# dm648_cslr_vport_001 register map
Vendor: Texas Instruments
Peripheral module from a debugger description file.
Registers are 32-bit, access not given, reset 0x0 unless marked. A register's access mark holds for its fields unless they carry their own. Offsets are as the file gives them; lines under a group give offsets from that group; [hi:lo] are bit positions; {n}, {i} and the like mark numbered series; 'fields as' and 'values as' point back to an identical list; <NAME> marks a mode.

## VPORT — This module provides an interface to program the VPORT (Video Port) registers. These registers are memory mapped.
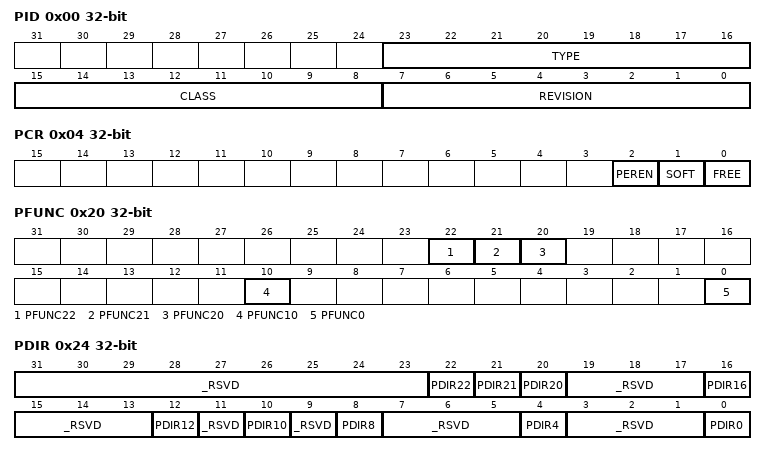
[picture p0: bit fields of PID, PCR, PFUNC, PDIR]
0x00 PID — Video Port Peripheral Identification Register
  [23:16] TYPE ro — Peripheral Type
  [15:8] CLASS ro — Peripheral Class
  [7:0] REVISION ro — Peripheral Revision
0x04 PCR — Video Port Peripheral Control Register
  [2] PEREN rw — Peripheral Enable
    0=INP_DIS; 1=PORT_FUNC
  [1] SOFT ro — Emulation suspend
    0=FLD_COMP_EMU_SUS; 1=ND
  [0] FREE rw — Port Operation during emulation suspension
    0=SOFT_DET; 1=PORT_ENA_EMU_SUS
0x20 PFUNC — Video Port Pin Function Register
  [22] PFUNC22 rw — Controls VCTL3
  [21] PFUNC21 rw — Controls VCTL2
  [20] PFUNC20 rw — Controls VCTL1
  [10] PFUNC10 rw — Controls VDATA[19:10]
    0=1BYTE
  [0] PFUNC0 rw — Controls VDATA[9:0]
0x24 PDIR — Video Port Direction Register
  [31:23] _RSVD — These bits are not used (access N)
  [22] PDIR22 rw — Controls VCTL3
  [21] PDIR21 rw — Controls VCTL2
  [20] PDIR20 rw — Controls VCTL1
  [19:17] _RSVD — These bits are not used (access N)
  [16] PDIR16 rw — Controls VDATA[19:16]
  [15:13] _RSVD — These bits are not used (access N)
  [12] PDIR12 rw — Controls VDATA[15:12]
  [11] _RSVD — These bits are not used (access N)
  [10] PDIR10 rw — Controls VDATA[11:10]
  [9] _RSVD — These bits are not used (access N)
  [8] PDIR8 rw — Controls VDATA[9:8]
  [7:5] _RSVD — These bits are not used (access N)
    1=ENABLE (Access the divisor latches)
  [4] PDIR4 rw — Controls VDATA[7:4]
    0=DISABLE (Access the RBR/THR and IER)
  [3:1] _RSVD — These bits are not used (access N)
  [0] PDIR0 rw — Controls VDATA[3:0]
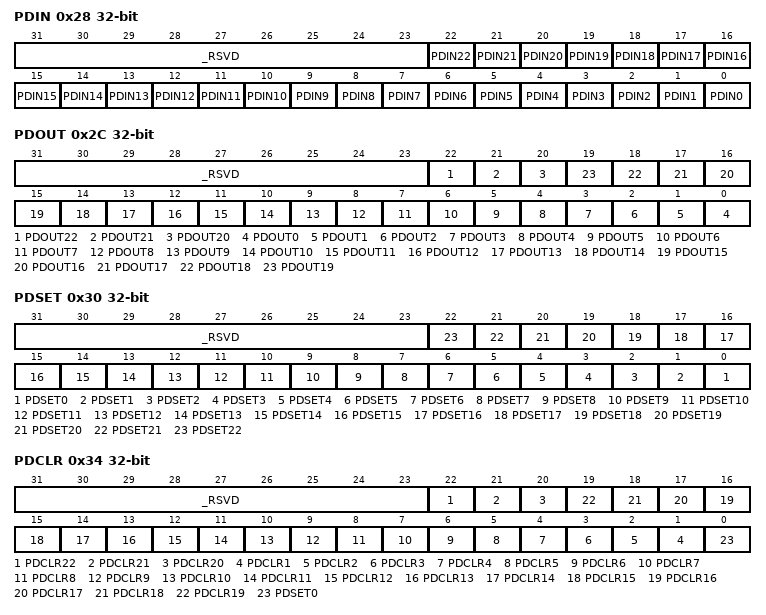
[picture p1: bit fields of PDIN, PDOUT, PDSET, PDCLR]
0x28 PDIN — Video Port Data In Register
  [31:23] _RSVD — These bits are not used (access N)
  [22] PDIN22 ro — Pin 22 returns the value of VCTL3 PIN
  [21] PDIN21 ro — Pin 21 returns the value of VCTL2 PIN
  [20] PDIN20 ro — Pin 20 returns the value of VCTL1 PIN
  [n] PDIN{n} ro (n=0..19) — Return the value of VDATA pins
0x2C PDOUT — Video Port Data Out Register
  [31:23] _RSVD — These bits are not used (access N)
  [22] PDOUT22 rw — Controls VCTL3
  [21] PDOUT21 rw — Controls VCTL2
  [20] PDOUT20 rw — Controls VCTL1
  [n] PDOUT{n} rw (n=0..19) — Controls VDATA
0x30 PDSET — Video Port Data Set Register
  [31:23] _RSVD — These bits are not used. (access N)
  [n] PDSET{n} rw (n=0..22) — Sets corresponding bit in PDOUT
0x34 PDCLR — Video Port Data Clear Register
  [31:23] _RSVD — These bits are not used. (access N)
  [22] PDCLR22 rw — Controls VCTL3
  [21] PDCLR21 rw — Controls VCTL2
  [20] PDCLR20 rw — Controls VCTL1
  [n] PDCLR{n} rw (n=1..19) — Clears corresponding bit in PDOUT
  [0] PDSET0 rw — Clears corresponding bit in PDOUT
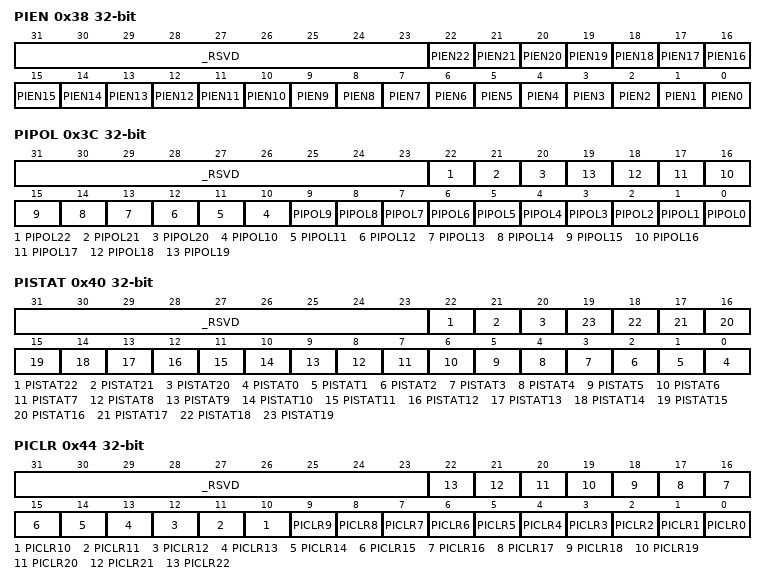
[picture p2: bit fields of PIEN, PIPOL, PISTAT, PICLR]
0x38 PIEN — Video Port Interrupt Enable
  [31:23] _RSVD — These bits are not used. (access N)
  [22] PIEN22 rw — Enable interrupt on VCTL3 pin
  [21] PIEN21 rw — Enable interrupt on VCTL2 pin
  [20] PIEN20 rw — Enable interrupt on VCTL1 pin
  [n] PIEN{n} rw (n=0..19) — Enable interrupt on corresponding VDATA pin
0x3C PIPOL — Video Port Interrupt Polarity Register
  [31:23] _RSVD — These bits are not used. (access N)
  [22] PIPOL22 rw — Controls interrupt on VCTL3
  [21] PIPOL21 rw — Controls interrupt on VCTL2
  [20] PIPOL20 rw — Controls interrupt on VCTL1
  [n] PIPOL{n} rw (n=2..19) — Controls interrupt on VDATA pin
  [1] PIPOL1 rw — Controls interrupt on VDATA
  [0] PIPOL0 rw — Controls interrupt on VDATA
0x40 PISTAT — Video Port Interrupt Status Register
  [31:23] _RSVD — These bits are not used. (access N)
  [22] PISTAT22 rw — Indicates pending interrupt on VCTL3 pin
  [21] PISTAT21 rw — Indicates pending interrupt on VCTL2 pin
  [20] PISTAT20 rw — Indicates pending interrupt on VCTL1 pin
  [n] PISTAT{n} rw (n=0..19) — Controls interrupt on VDATA pin
0x44 PICLR — Video Port Interrupt Clear Register
  [31:23] _RSVD — These bits are not used. (access N)
  [n] PICLR{n} rw (n=0..22) — Writing 1 to PICLR clears corresponding bit in PISTAT
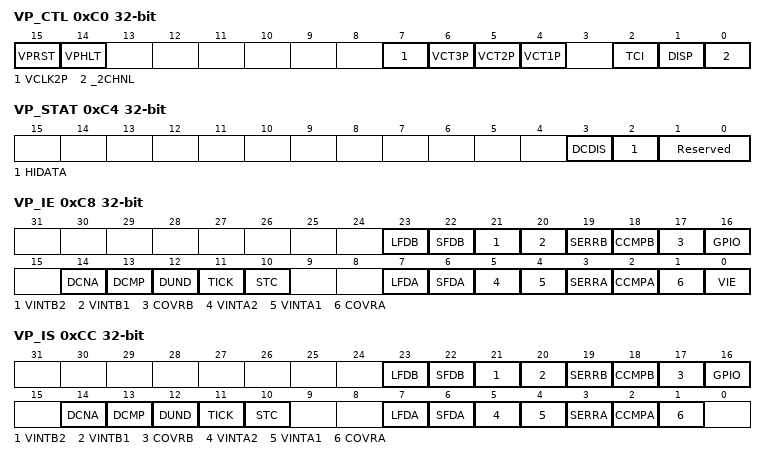
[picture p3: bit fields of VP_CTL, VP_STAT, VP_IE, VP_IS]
0xC0 VP_CTL — Video Port Control Register
  [15] VPRST ro — Video Port Software Reset
  [14] VPHLT ro — Video Port Halt
  [7] VCLK2P rw — VCTL1 Pin Polarity
  [6] VCT3P rw — VCTL1 Pin Polarity
  [5] VCT2P rw — VCTL1 Pin Polarity
  [4] VCT1P rw — VCTL1 Pin Polarity
  [2] TCI rw — TCI Capture Mode
  [1] DISP rw — Display Mode
  [0] _2CHNL rw — Dual Channel Mode
0xC4 VP_STAT — Video Port Status Register
  [3] DCDIS ro — Dual Channel Disabled
  [2] HIDATA ro — High Data Half bus
  [1:0] Reserved — (access N)
0xC8 VP_IE — Video Port Interrupt Enable Register
  [23] LFDB rw — Lonfg field detected
  [22] SFDB rw — Short field detected
  [21] VINTB2 rw — Field 2 vertical interrupt enable
  [20] VINTB1 rw — Field 1 Vertical interrupt enable
  [19] SERRB rw — Synchronization
  [18] CCMPB rw — Capture complete on A/B channel interrupt enable
  [17] COVRB rw — Capture overrun on A/B channel interrupt enable
  [16] GPIO rw — General Purpose I/O
  [14] DCNA rw — Display complete not acknowledge
  [13] DCMP rw — Display complete
  [12] DUND rw — Display underrun
  [11] TICK rw — Clock tick
  [10] STC rw — System time clock
  [7] LFDA rw — Lonfg field detected
  [6] SFDA rw — Short field detected
  [5] VINTA2 rw — Field 2 vertical interrupt enable
  [4] VINTA1 rw — Field 1 Vertical interrupt enable
  [3] SERRA rw — Synchronization
  [2] CCMPA rw — Capture complete on A/B channel interrupt enable
  [1] COVRA rw — Capture overrun on A/B channel interrupt enable
  [0] VIE rw — Video Port global interrupt enable
0xCC VP_IS — Video Port Interrupt Status Register
  [23] LFDB rw — Lonfg field detected
  [22] SFDB rw — Short field detected
  [21] VINTB2 rw — Field 2 vertical interrupt enable
  [20] VINTB1 rw — Field 1 Vertical interrupt enable
  [19] SERRB rw — Synchronization
  [18] CCMPB rw — Capture complete on A/B channel interrupt enable
  [17] COVRB rw — Capture overrun on A/B channel interrupt enable
  [16] GPIO rw — General Purpose I/O
  [14] DCNA rw — Display complete not acknowledge
  [13] DCMP rw — Display complete
  [12] DUND rw — Display underrun
  [11] TICK rw — Clock tick
  [10] STC rw — System time clock
  [7] LFDA rw — Lonfg field detected
  [6] SFDA rw — Short field detected
  [5] VINTA2 rw — Field 2 vertical interrupt enable
  [4] VINTA1 rw — Field 1 Vertical interrupt enable
  [3] SERRA rw — Synchronization
  [2] CCMPA rw — Capture complete on A/B channel interrupt enable
  [1] COVRA rw — Capture overrun on A/B channel interrupt enable
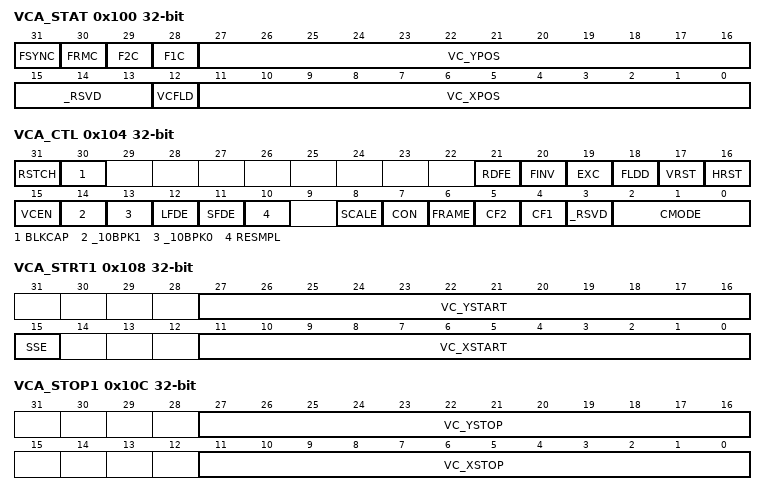
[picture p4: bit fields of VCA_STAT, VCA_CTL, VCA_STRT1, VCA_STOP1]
0x100 VCA_STAT — Video Capture Status Register
  [31] FSYNC ro — Sync to the current frame
  [30] FRMC ro — Indicates frame capture
  [29] F2C ro — Indicates field 2 capture
  [28] F1C ro — Indicates field 1 capture
  [27:16] VC_YPOS rw — Indicates line that is currently being received
  [15:13] _RSVD — These bits are not used. (access N)
  [12] VCFLD ro — Indicates which field is currently being captured
  [11:0] VC_XPOS ro — Pixel index of last received pixel
0x104 VCA_CTL — Video Capture Control Register
  [31] RSTCH rw
  [30] BLKCAP rw — Block
  [21] RDFE rw
  [20] FINV rw — Detected Field invert
  [19] EXC rw — Enable extenal control
  [18] FLDD rw — Field Detect
  [17] VRST rw — VCOUNT Reset method
  [16] HRST rw — HCOUNT reset method
  [15] VCEN rw — Video Capture Enable
  [14] _10BPK1 rw — Packing Format
  [13] _10BPK0 rw — Packing Format
  [12] LFDE rw — Long Field Detect
  [11] SFDE rw — Short Field Detect
  [10] RESMPL rw — Resampling
  [8] SCALE rw — Scaling
  [7] CON rw — Continuous capture enable
  [6] FRAME rw — Capture Frame
  [5] CF2 rw — Capture Field2
  [4] CF1 rw — Capture Field1
  [3] _RSVD — These bits are not used. (access N)
  [2:0] CMODE rw — Mode in which port should work
0x108 VCA_STRT1 — Video Captur Field1 Start Register
  [27:16] VC_YSTART — Starting Line Number
  [15] SSE rw — This bit determines over-sampling mode.
  [11:0] VC_XSTART — These bits are not used. (access N)
0x10C VCA_STOP1 — Video Capture Field1 Stop Register
  [27:16] VC_YSTOP rw — This bit determines over-sampling mode.
  [11:0] VC_XSTOP — These bits are not used. (access N)
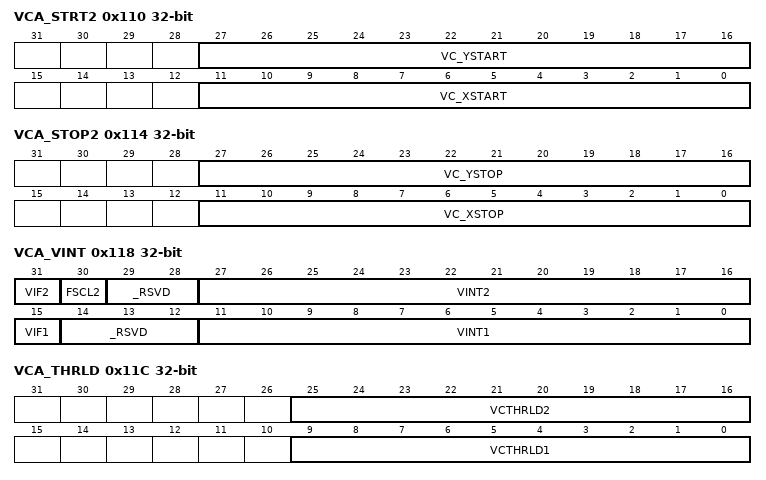
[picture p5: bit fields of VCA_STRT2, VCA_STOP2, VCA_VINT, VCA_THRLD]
0x110 VCA_STRT2 — Video Capture A Field2 Start Register
  [27:16] VC_YSTART rw — This bit determines over-sampling mode.
  [11:0] VC_XSTART — These bits are not used. (access N)
0x114 VCA_STOP2 — Video Capture A Field2 Stop Register
  fields as VCA_STOP1
0x118 VCA_VINT — Video Capture Vertical Interrupt Register
  [31] VIF2 rw — Enable setting of VINT in field 2
  [30] FSCL2 rw — FSYNC bit to be cleared in field 2
  [29:28] _RSVD — This bit determines over-sampling mode. (access N)
  [27:16] VINT2 rw — Line on which vertical interrupt occurs
  [15] VIF1 rw — Enable setting of VINT1 in field 1
  [14:12] _RSVD — These bits are not used. (access N)
  [11:0] VINT1 rw — Enable setting of VINT in field 2
0x11C VCA_THRLD — Video Capture Threshold Register
  [25:16] VCTHRLD2 rw — Field 2 threshold
  [9:0] VCTHRLD1 — Field 1 threshold (access N)
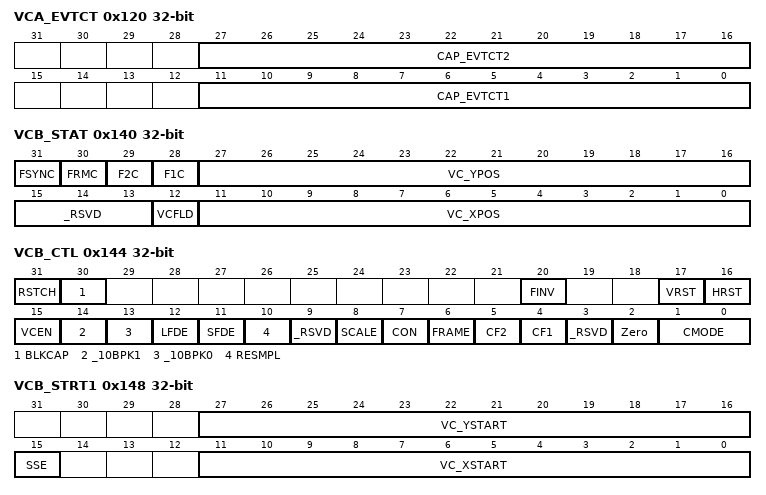
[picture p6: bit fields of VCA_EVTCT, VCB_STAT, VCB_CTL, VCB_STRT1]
0x120 VCA_EVTCT — Video Capture Event Count Register
  [27:16] CAP_EVTCT2 rw — DMA event for field 2 capture
  [11:0] CAP_EVTCT1 — DMA event for field 1 capture (access N)
0x140 VCB_STAT — Video Capture Status Register
  fields as VCA_STAT
0x144 VCB_CTL — Video Capture Control Register
  [31] RSTCH rw
  [30] BLKCAP rw — Block
  [20] FINV rw — Detected Field invert
  [17] VRST rw — VCOUNT Reset method
  [16] HRST rw — HCOUNT reset method
  [15] VCEN rw — Video Capture Enable
  [14] _10BPK1 rw — Packing Format
  [13] _10BPK0 rw — Packing Format
  [12] LFDE rw — Long Field Detect
  [11] SFDE rw — Short Field Detect
  [10] RESMPL rw — Resampling
  [9] _RSVD — Resampling (access N)
  [8] SCALE rw — Scaling
  [7] CON rw — Continuous capture enable
  [6] FRAME rw — Capture Frame
  [5] CF2 rw — Capture Field2
  [4] CF1 rw — Capture Field1
  [3] _RSVD — These bits are not used. (access N)
  [2] Zero ro — Value is zero
  [1:0] CMODE rw — Mode in which port should work
0x148 VCB_STRT1 — Video Captur Field1 Start Register
  fields as VCA_STRT1
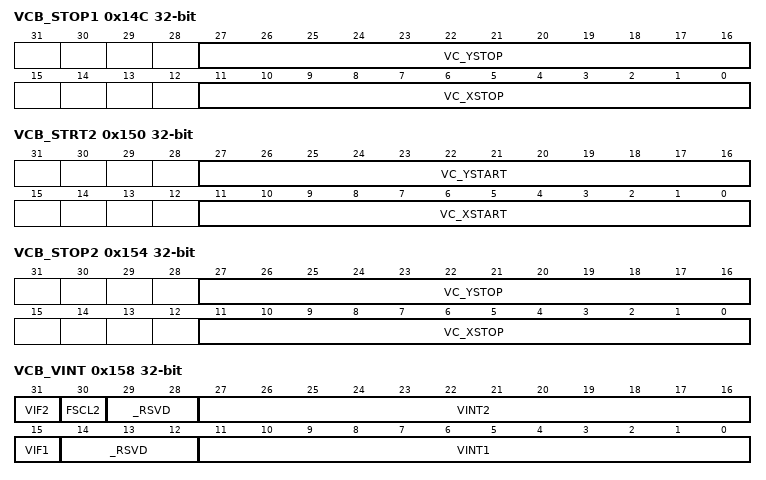
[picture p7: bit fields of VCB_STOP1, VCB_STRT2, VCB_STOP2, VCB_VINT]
0x14C VCB_STOP1 — Video Capture Field1 Stop Register
  fields as VCA_STOP1
0x150 VCB_STRT2 — Video Capture B Field2 Start Register
  fields as VCA_STRT2
0x154 VCB_STOP2 — Video Capture B Field2 Stop Register
  fields as VCA_STOP1
0x158 VCB_VINT — Video Capture Vertical Interrupt Register
  fields as VCA_VINT
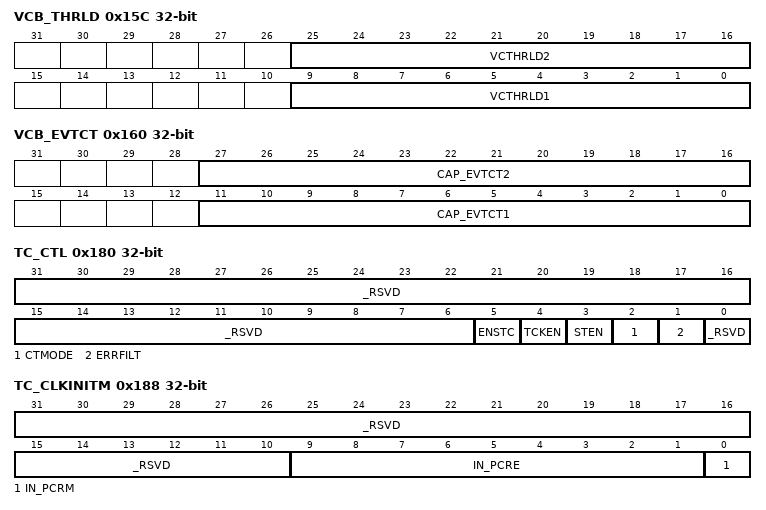
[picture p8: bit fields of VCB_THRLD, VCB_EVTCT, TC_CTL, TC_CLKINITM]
0x15C VCB_THRLD — Video Capture Vertical Interrupt Register
  fields as VCA_THRLD
0x160 VCB_EVTCT — Video Capture B Event Count Register
  fields as VCA_EVTCT
0x180 TC_CTL — TCI Capture Control Register
  [31:6] _RSVD — These bits are not used. (access N)
  [5] ENSTC rw — Enable system time clock
    1=ENABLE; 0=DISABLE
  [4] TCKEN rw — Enable tick count interrupt
    1=ENABLE; 0=DISABLE
  [3] STEN rw — Enable system time clock interrupt
    1=ENABLE; 0=DISABLE
  [2] CTMODE rw — Counter Mode
    0=INC-90; 1=INC-STCLK
  [1] ERRFILT — Enable error filtering (access N)
    0=RECEIVED; 1=FILTERED
  [0] _RSVD — These bits are not used. (access N)
0x184 TC_CLKINITL rw — TCI Clock Initialization LSB Register
  [31:0] IN_PCR — Initialize the hardware counter to system time clock
0x188 TC_CLKINITM — TCI Clock Initialization MSB Register
  [31:10] _RSVD — These bits are not used. (access N)
  [9:1] IN_PCRE rw — Initialize to synchronize system time clock
  [0] IN_PCRM rw — Initialize the MSB of system time clock
0x18C TC_STCLKL ro — TCI System Time Clock LSB Register
  [31:0] PCR — Read system time clock
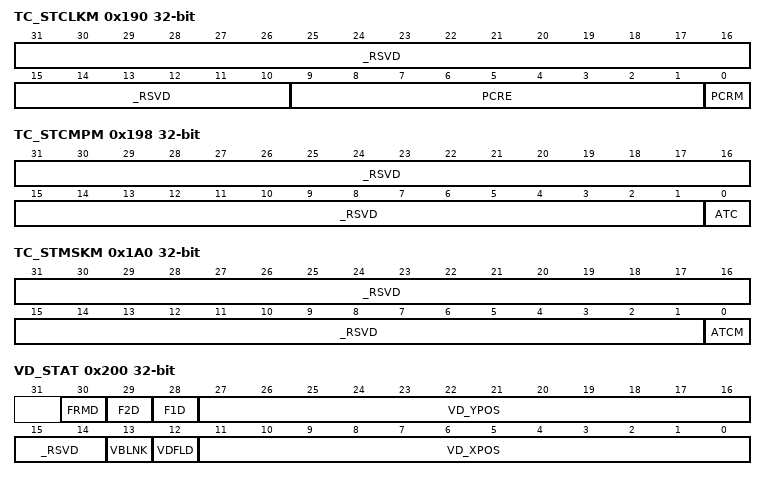
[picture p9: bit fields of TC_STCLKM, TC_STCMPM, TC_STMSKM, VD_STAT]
0x190 TC_STCLKM — TCI System Time Clock MSB Register
  [31:10] _RSVD — These bits are not used. (access N)
  [9:1] PCRE ro
  [0] PCRM ro
0x194 TC_STCMPL rw — TCI STC Compare LSB Register
  [31:0] ATC — Absolute time compare
0x198 TC_STCMPM — TCI STC Compare MSB Register
  [31:1] _RSVD — These bits are not used. (access N)
  [0] ATC rw — Absolute time compare
0x19C TC_STMSKL rw — TCI STC Compare Mask LSB Register
  [31:0] ATCM — Absolute time compare mask
0x1A0 TC_STMSKM — TCI STC Compare Mask MSB Register
  [31:1] _RSVD — These bits are not used. (access N)
  [0] ATCM rw — Absolute time compare mask
0x1A4 TC_TICKS rw — TCI STC Tick Count Register
  [31:0] TICKCT — Used to generate an interrupt after certain ticks
0x200 VD_STAT — Video Display Status
  [30] FRMD ro — Complete frame displayed
  [29] F2D ro — Field 1 displayed
    0=FLD2; 1=CLEAR
  [28] F1D ro — Field 1 displayed
    0=FLD1; 1=CLEAR
  [27:16] VD_YPOS ro — This bit determines over-sampling mode.
  [15:14] _RSVD — These bits are not used. (access N)
  [13] VBLNK ro — Vertical blanking
  [12] VDFLD ro — Indicates which field displayed
    0=FLD1; 1=FLD2
  [11:0] VD_XPOS ro — Index of most recently output pixel
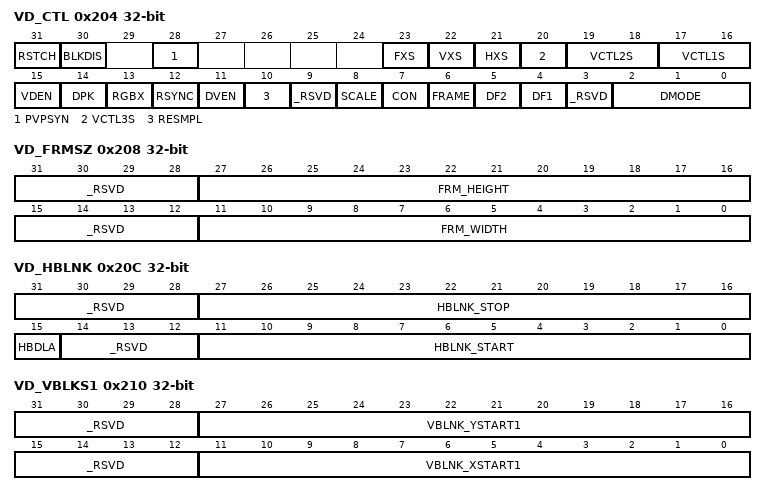
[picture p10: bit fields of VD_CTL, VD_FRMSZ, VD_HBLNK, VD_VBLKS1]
0x204 VD_CTL — Video Display Control
  [31] RSTCH rw
    0=NA; 1=RESET
  [30] BLKDIS rw — Block display events
  [28] PVPSYN rw — Video Port synchronization
  [23] FXS rw — Field external sync
    0=VCTL3O/P; 1=VCTL3I/P
  [22] VXS rw — Vertical external sync
    0=VCTL2O/P; 1=VCTL2I/P
  [21] HXS rw — Horizontal external sync
    0=VCTL1O/P; 1=VCTL1I/P
  [20] VCTL3S rw — VCTL3 output select
    0=CBLNK; 1=FLD
  [19:18] VCTL2S rw — VCTL2 output select
  [17:16] VCTL1S rw — VCTL1 output select
  [15] VDEN rw — video display enabled
  [14] DPK rw — Bit packing
    0=NORMAL; 1=DENSE
  [13] RGBX rw — RGB extract enable
  [12] RSYNC rw
  [11] DVEN rw — Default value enable
    0=BLNKOUTPUT; 1=DEFOUTPUT
  [10] RESMPL rw — Short Field Detect
    0=DISABLE; 1=ENABLE
  [9] _RSVD — Resampling (access N)
  [8] SCALE rw — Scaling
    0=DISABLE; 1=ENABLE
  [7] CON rw — Continuous capture enable
  [6] FRAME rw — Capture Frame
  [5] DF2 rw — Capture Field2
  [4] DF1 rw — Capture Field1
  [3] _RSVD — These bits are not used. (access N)
  [2:0] DMODE rw — Mode in which port should work
0x208 VD_FRMSZ — Video Display Frame Size
  [31:28] _RSVD — These bits are not used. (access N)
  [27:16] FRM_HEIGHT rw — Defines the total number of lines per frame
  [15:12] _RSVD — These bits are not used. (access N)
  [11:0] FRM_WIDTH rw — Defines the total number of pixels per line during blanking
0x20C VD_HBLNK — Video Display Horizontal Blanking
  [31:28] _RSVD — These bits are not used. (access N)
  [27:16] HBLNK_STOP rw — Indicates location of SAV code and HBLNK inactive edge within the line
  [15] HBDLA rw — When set,delays HBLNK inactive edge by 4 VCLKs
  [14:12] _RSVD — These bits are not used. (access N)
  [11:0] HBLNK_START rw — Indicates location of EAV code and HBLNK active edge within the line
0x210 VD_VBLKS1 — Video Display Vertical Blanking Start-Field 1
  [31:28] _RSVD — These bits are not used. (access N)
  [27:16] VBLNK_YSTART1 rw — Specifies the line on which VBLNK active edge occurs for field 1
  [15:12] _RSVD — These bits are not used. (access N)
  [11:0] VBLNK_XSTART1 rw — Specifies the pixel on which VBLNK active edge occurs for field 1
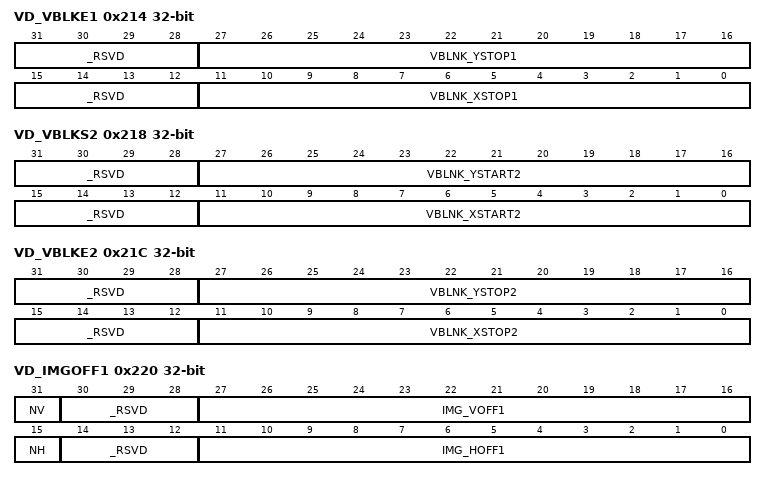
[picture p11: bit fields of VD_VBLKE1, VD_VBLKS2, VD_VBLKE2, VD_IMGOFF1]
0x214 VD_VBLKE1 — Video Display Vertical Blanking End-Field1
  [31:28] _RSVD — These bits are not used. (access N)
  [27:16] VBLNK_YSTOP1 rw — Specifies the line on which VBLNK inactive edge occurs for field 1
  [15:12] _RSVD — These bits are not used. (access N)
  [11:0] VBLNK_XSTOP1 rw — Specifies the pixel on which VBLNK inactive edge occurs for field 1
0x218 VD_VBLKS2 — Video Display Vertical Blanking Start-Field2
  [31:28] _RSVD — These bits are not used. (access N)
  [27:16] VBLNK_YSTART2 rw — Specifies the line on which VBLNK active edge occurs for field 2
  [15:12] _RSVD — These bits are not used. (access N)
  [11:0] VBLNK_XSTART2 rw — Specifies the pixel on which VBLNK active edge occurs for field 2
0x21C VD_VBLKE2 — Video Display Vertical Blanking End-Field2
  [31:28] _RSVD — These bits are not used. (access N)
  [27:16] VBLNK_YSTOP2 rw — Specifies the line on which VBLNK inactive edge occurs for field 2
  [15:12] _RSVD — These bits are not used. (access N)
  [11:0] VBLNK_XSTOP2 rw — Specifies the pixel on which VBLNK inactive edge occurs for field 2
0x220 VD_IMGOFF1 — Video Display Image Offset-Field 1
  [31] NV rw — Not used
  [30:28] _RSVD — These bits are not used. (access N)
  [27:16] IMG_VOFF1 rw — Specifies the display image height in lines
  [15] NH — Not used
  [14:12] _RSVD — These bits are not used. (access N)
  [11:0] IMG_HOFF1 rw — Specifies the display image width in pixels
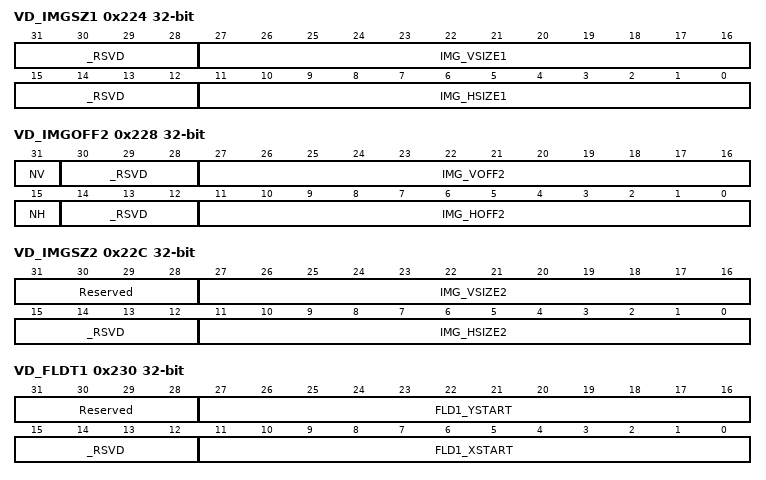
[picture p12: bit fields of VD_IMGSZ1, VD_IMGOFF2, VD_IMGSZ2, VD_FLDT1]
0x224 VD_IMGSZ1 — Video Display Image Size-Field 1
  [31:28] _RSVD — These bits are not used. (access N)
  [27:16] IMG_VSIZE1 rw — Specifies the display image height in lines
  [15:12] _RSVD — These bits are not used. (access N)
  [11:0] IMG_HSIZE1 rw — Specifies the display image width in pixels
0x228 VD_IMGOFF2 — Video Display Image Offset-Field 2
  [31] NV rw
  [30:28] _RSVD — These bits are not used. (access N)
  [27:16] IMG_VOFF2 rw — Specifies the display image height in lines
  [15] NH
  [14:12] _RSVD — These bits are not used. (access N)
  [11:0] IMG_HOFF2 rw — Specifies the display image width in pixels
0x22C VD_IMGSZ2 — Video Display Image Size-Field 2
  [31:28] Reserved — (access N)
  [27:16] IMG_VSIZE2 rw — Specifies the display image height in lines
  [15:12] _RSVD — These bits are not used. (access N)
  [11:0] IMG_HSIZE2 rw — Specifies the display image width in pixels
0x230 VD_FLDT1 — Video Display Field1 Timing
  [31:28] Reserved — (access N)
  [27:16] FLD1_YSTART rw — Specifies the first line of field1
  [15:12] _RSVD — These bits are not used. (access N)
  [11:0] FLD1_XSTART rw — Specifies the pixel on the first line of field1 on which FLD output is deasserted
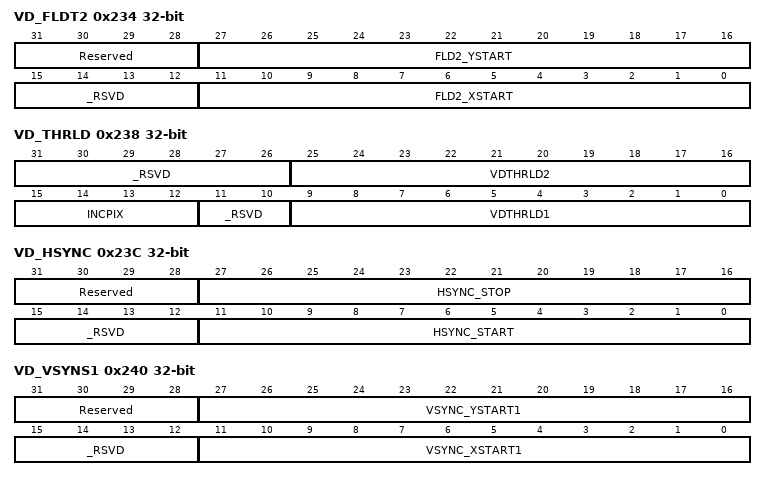
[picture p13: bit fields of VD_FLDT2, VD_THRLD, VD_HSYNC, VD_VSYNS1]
0x234 VD_FLDT2 — Video Display Field2 Timing
  [31:28] Reserved — (access N)
  [27:16] FLD2_YSTART rw — Specifies the first line of field2 .
  [15:12] _RSVD — These bits are not used. (access N)
  [11:0] FLD2_XSTART rw — Specifies the pixel on the first line of field2 on which FLD output is asserted
0x238 VD_THRLD — Video Display Threshold register
  [31:26] _RSVD — These bits are not used. (access N)
  [25:16] VDTHRLD2 rw — Field 2 threshold
  [15:12] INCPIX rw — FPCOUNT increment in display mode
  [11:10] _RSVD — These bits are not used. (access N)
  [9:0] VDTHRLD1 rw — Field 1 threshold
0x23C VD_HSYNC — Video Display Horizontal Sync
  [31:28] Reserved — (access N)
  [27:16] HSYNC_STOP rw — Specifies the line on which HSYNC is desserted
  [15:12] _RSVD — These bits are not used. (access N)
  [11:0] HSYNC_START rw — Specifies the pixel on which HSYNC is asserted
0x240 VD_VSYNS1 — Video Display Vertical Synchronization Start-Field 1
  [31:28] Reserved — (access N)
  [27:16] VSYNC_YSTART1 rw — Specifies the line on which VSYNC is asserted on field 1
  [15:12] _RSVD — These bits are not used. (access N)
  [11:0] VSYNC_XSTART1 rw — Specifies the pixel on which VSYNC is asserted on field 1
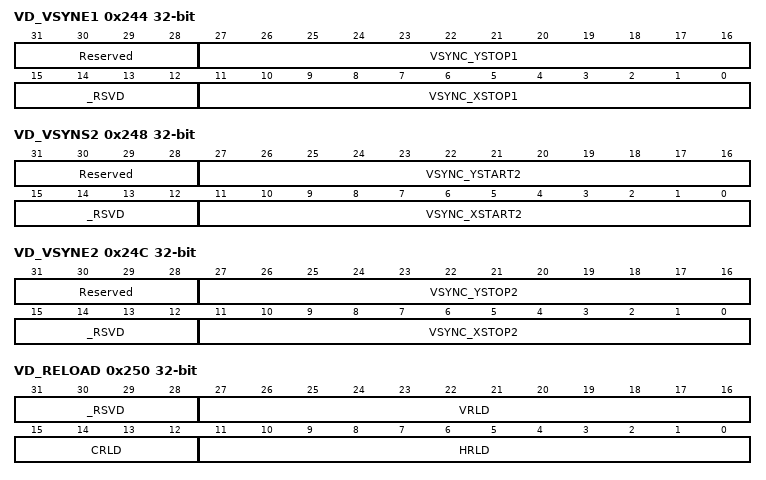
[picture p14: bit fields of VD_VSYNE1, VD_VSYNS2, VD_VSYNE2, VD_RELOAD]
0x244 VD_VSYNE1 — Video Display Vertical Synchronization End-Field 1
  [31:28] Reserved — (access N)
  [27:16] VSYNC_YSTOP1 rw — Specifies the line on which VSYNC is deasserted on field 1
  [15:12] _RSVD — These bits are not used. (access N)
  [11:0] VSYNC_XSTOP1 rw — Specifies the pixel on which VSYNC is deasserted on field 1
0x248 VD_VSYNS2 — Video Display Vertical Synchronization Start-Field 2
  [31:28] Reserved — (access N)
  [27:16] VSYNC_YSTART2 rw — Specifies the line on which VSYNC is asserted on field 2
  [15:12] _RSVD — These bits are not used. (access N)
  [11:0] VSYNC_XSTART2 rw — Specifies the pixel on which VSYNC is asserted on field 2
0x24C VD_VSYNE2 — Video Display Vertical Synchronization End-Field 2
  [31:28] Reserved — (access N)
  [27:16] VSYNC_YSTOP2 rw — Specifies the line on which VSYNC is deasserted on field 2
  [15:12] _RSVD — These bits are not used. (access N)
  [11:0] VSYNC_XSTOP2 rw — Specifies the pixel on which VSYNC is deasserted on field 2
0x250 VD_RELOAD — Video Display Default Display Value
  [31:28] _RSVD — These bits are not used. (access N)
  [27:16] VRLD rw — Value loaded into FLCOUNT when external VSYNC occurs
  [15:12] CRLD ro — Value loaded into VCCOUNT when external HSYNC occurs
  [11:0] HRLD rw — Value loaded into FPCOUNT when external HSYNC occurs
0x254 VD_DISPEVT — Video Display Default Display Value
  [31:28] _RSVD — These bits are not used. (access N)
  [27:16] DISPEVT2 rw — Specifies DMA event state to be generated for field 2 output
  [15:12] _RSVD — These bits are not used. (access N)
  [11:0] DISPEVT1 rw — Specifies DMA event state to be generated for field 1 output
0x258 VD_CLIP rw — Video Display Clipping Register
  [31:24] CLIPC_HI — A Cb or Cr value greater than CLIPY_HIGH is forced to CLIPY_HIGH value
  [23:16] CLIPC_LO — A Y value less than CLIPY_LOW is forced to CLIPY_LOW value
  [15:8] CLIPY_HI — A Cb or Cr value greater than CLIPY_HIGH is forced to CLIPY_HIGH value
  [7:0] CLIPY_LO — A Y value less than CLIPY_LOW is forced to CLIPY_LOW value
0x25C VD_DEFVAL rw — Video Display Default Display Value
  [31:24] CrDEFVAL — Specifies the 8 MS bits of default Cr display value
  [23:16] CbDEFVAL — Specifies the 8 MS bits of default Cb display value
  [15:8] Not_Used
  [7:0] YDEFVAL — Specifies the 8 MS bits of default Y display value
0x260 VD_VINT — Video Display Vertical Interrupt
  [31] V1F2 rw — Enables setting of VINT in field2
  [30:28] _RSVD — These bits are not used. (access N)
  [27:16] VINT2 rw — These bits are not used.
  [15] V1F1 rw
  [14:12] _RSVD — These bits are not used. (access N)
  [11:0] VINT1 rw — These bits are not used.
0x264 VD_FBIT — Video Display Field Bit
  [31:28] _RSVD — These bits are not used. (access N)
  [27:16] FBIT_SET — Specifies the first line with an EAV of F = 1 indicating field 2 display (access N)
  [15:12] _RSVD — These bits are not used. (access N)
  [11:0] FBIT_CLR rw — Control F bit value in EAV/SAV timing control modes
0x268 VD_VBIT1 — Video Display Vertical Blanking Bit-Field 1
  [31:28] _RSVD — These bits are not used. (access N)
  [27:16] VBIT_CLR1 rw — Control V bit value in EAV/SAV timing control modes
  [15:12] _RSVD — These bits are not used. (access N)
  [11:0] VBIT_SET1 rw — Control V bit value in EAV/SAV timing control modes
0x26C VD_VBIT2 — Video Display Vertical Blanking Bit-Field 2
  [31:28] _RSVD — These bits are not used. (access N)
  [27:16] VBIT_CLR2 rw — Control V bit value in EAV/SAV timing control modes
  [15:12] _RSVD — These bits are not used. (access N)
  [11:0] VBIT_SET2 rw — Control V bit value in EAV/SAV timing control modes
